# ATSAMD21G17L register map
Vendor: Microchip Technology Inc.; Series: SAMD21; File version: G
CPU: CM0+ r0p1, little endian, no MPU, no FPU, VTOR, 2 interrupt priority bits, 30 interrupts
Registers are 32-bit, read-write, reset 0x0 unless marked. A register's access mark holds for its fields unless they carry their own. Offsets are from the block's base; [hi:lo] are bit positions; lines under a group give offsets from that group; 'fields as' and 'values as' point back to an identical list.

## SERCOM0 — Serial Communication Interface 0
Base 0x42000800; register names take the prefix SERCOM_
Same registers: SERCOM1 0x42000C00, SERCOM2 0x42001000, SERCOM3 0x42001400, SERCOM4 0x42001800, SERCOM5 0x42001C00
0x00 I2CM group — I2C Master Mode
  0x00 CTRLA — I2CM Control A
    [30] LOWTOUTEN — SCL Low Timeout Enable
    [29:28] INACTOUT — Inactive Time-Out
    [27] SCLSM — SCL Clock Stretch Mode
    [25:24] SPEED — Transfer Speed
      0=STANDARD_AND_FAST_MODE (Standard Mode(Sm) Upto 100kHz and Fast Mode(Fm) Upto 400kHz); 1=FASTPLUS_MODE (Fast-mode Plus Upto 1MHz); 2=HIGH_SPEED_MODE (High-speed mode Upto 3.4MHz)
    [23] SEXTTOEN — Slave SCL Low Extend Timeout
    [22] MEXTTOEN — Master SCL Low Extend Timeout
    [21:20] SDAHOLD — SDA Hold Time
      0=DISABLE (Disabled); 1=75NS (50-100ns hold time); 2=450NS (300-600ns hold time); 3=600NS (400-800ns hold time)
    [16] PINOUT — Pin Usage
    [7] RUNSTDBY — Run in Standby
    [4:2] MODE — Operating Mode
      0=USART_EXT_CLK (USART mode with external clock); 1=USART_INT_CLK (USART mode with internal clock); 2=SPI_SLAVE (SPI mode with external clock); 3=SPI_MASTER (SPI mode with internal clock); 4=I2C_SLAVE (I2C mode with external clock); 5=I2C_MASTER (I2C mode with internal clock)
    [1] ENABLE
    [0] SWRST — Software Reset
  0x04 CTRLB — I2CM Control B
    [18] ACKACT — Acknowledge Action
      0=Send_ACK (sending ack); 1=Send_NACK (sending nack)
    [17:16] CMD — Command
      0=no_action; 1=ack_repeated_start (Execute acknowledge action succeeded by repeated Start); 2=ack_byte_read (Execute acknowledge action succeeded by a byte read operation); 3=ack_stop (Execute acknowledge action succeeded by issuing a stop condition)
    [9] QCEN — Quick Command Enable
    [8] SMEN — Smart Mode Enable
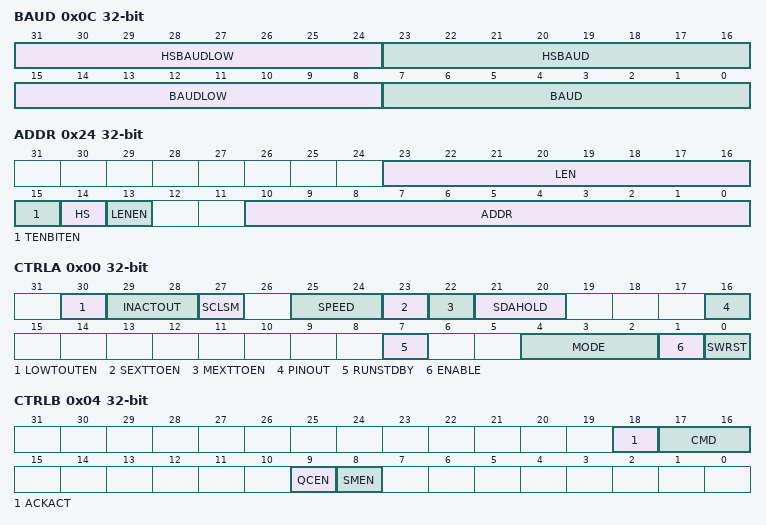
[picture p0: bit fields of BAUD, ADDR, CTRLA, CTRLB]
  0x0C BAUD — I2CM Baud Rate
    [31:24] HSBAUDLOW — High Speed Baud Rate Value Low
    [23:16] HSBAUD — High Speed Baud Rate Value
    [15:8] BAUDLOW — Baud Rate Value Low
    [7:0] BAUD — Baud Rate Value
  0x14 INTENCLR 8-bit — I2CM Interrupt Enable Clear
    [7] ERROR — Combined Error Interrupt Disable
    [1] SB — Slave On Bus Interrupt Disable
    [0] MB — Master On Bus Interrupt Disable
  0x16 INTENSET 8-bit — I2CM Interrupt Enable Set
    [7] ERROR — Combined Error Interrupt Enable
    [1] SB — Slave On Bus Interrupt Enable
    [0] MB — Master On Bus Interrupt Enable
  0x18 INTFLAG 8-bit — I2CM Interrupt Flag Status and Clear
    [7] ERROR write-1-clears — Combined Error Interrupt
    [1] SB write-1-clears — Slave On Bus Interrupt
    [0] MB write-1-clears — Master On Bus Interrupt
  0x1A STATUS 16-bit — I2CM Status
    [10] LENERR write-1-clears — Length Error
    [9] SEXTTOUT write-1-clears — Slave SCL Low Extend Timeout
    [8] MEXTTOUT write-1-clears — Master SCL Low Extend Timeout
    [7] CLKHOLD ro — Clock Hold
    [6] LOWTOUT write-1-clears — SCL Low Timeout
    [5:4] BUSSTATE
      0=unknown (The bus state is unknown to the I2C master and will wait for a stop condition to be detected or wait to be forced into an idle state by software); 1=idle (The bus state is waiting for a transaction to be initialized); 2=owner (The I2C master is the current owner of the bus); 3=busy (Some other I2C master owns the bus)
    [2] RXNACK ro — Received Not Acknowledge
    [1] ARBLOST write-1-clears — Arbitration Lost
    [0] BUSERR write-1-clears — Bus Error
  0x1C SYNCBUSY ro — I2CM Synchronization Busy
    [2] SYSOP — System Operation Synchronization Busy
    [1] ENABLE — SERCOM Enable Synchronization Busy
    [0] SWRST — Software Reset Synchronization Busy
  0x24 ADDR — I2CM Address
    [23:16] LEN — Length
    [15] TENBITEN — Ten Bit Addressing Enable
    [14] HS — High Speed Mode
    [13] LENEN — Length Enable
    [10:0] ADDR — Address Value
  0x28 DATA 8-bit — I2CM Data
    [7:0] DATA — Data Value
  0x30 DBGCTRL 8-bit — I2CM Debug Control
    [0] DBGSTOP — Debug Mode
0x00 I2CS group (alternate view of I2CM) — I2C Slave Mode
  0x00 CTRLA — I2CS Control A
    [30] LOWTOUTEN — SCL Low Timeout Enable
    [27] SCLSM — SCL Clock Stretch Mode
    [25:24] SPEED — Transfer Speed
    [23] SEXTTOEN — Slave SCL Low Extend Timeout
    [21:20] SDAHOLD — SDA Hold Time
    [16] PINOUT — Pin Usage
    [7] RUNSTDBY — Run during Standby
    [4:2] MODE — Operating Mode
      values as I2CM.CTRLA.MODE
    [1] ENABLE
    [0] SWRST — Software Reset
  0x04 CTRLB — I2CS Control B
    [18] ACKACT — Acknowledge Action
    [17:16] CMD wo write-1-sets — Command
    [15:14] AMODE — Address Mode
    [10] AACKEN — Automatic Address Acknowledge
    [9] GCMD — PMBus Group Command
    [8] SMEN — Smart Mode Enable
  0x14 INTENCLR 8-bit — I2CS Interrupt Enable Clear
    [7] ERROR — Combined Error Interrupt Disable
    [2] DRDY — Data Interrupt Disable
    [1] AMATCH — Address Match Interrupt Disable
    [0] PREC — Stop Received Interrupt Disable
  0x16 INTENSET 8-bit — I2CS Interrupt Enable Set
    [7] ERROR — Combined Error Interrupt Enable
    [2] DRDY — Data Interrupt Enable
    [1] AMATCH — Address Match Interrupt Enable
    [0] PREC — Stop Received Interrupt Enable
  0x18 INTFLAG 8-bit — I2CS Interrupt Flag Status and Clear
    [7] ERROR write-1-clears — Combined Error Interrupt
    [2] DRDY write-1-clears — Data Interrupt
    [1] AMATCH write-1-clears — Address Match Interrupt
    [0] PREC write-1-clears — Stop Received Interrupt
  0x1A STATUS 16-bit — I2CS Status
    [10] HS write-1-clears — High Speed
    [9] SEXTTOUT write-1-clears — Slave SCL Low Extend Timeout
    [7] CLKHOLD ro — Clock Hold
    [6] LOWTOUT write-1-clears — SCL Low Timeout
    [4] SR ro — Repeated Start
    [3] DIR ro — Read/Write Direction
    [2] RXNACK ro — Received Not Acknowledge
    [1] COLL write-1-clears — Transmit Collision
    [0] BUSERR write-1-clears — Bus Error
  0x1C SYNCBUSY ro — I2CS Synchronization Busy
    [1] ENABLE — SERCOM Enable Synchronization Busy
    [0] SWRST — Software Reset Synchronization Busy
  0x24 ADDR — I2CS Address
    [26:17] ADDRMASK — Address Mask
    [15] TENBITEN — Ten Bit Addressing Enable
    [10:1] ADDR — Address Value
    [0] GENCEN — General Call Address Enable
  0x28 DATA 8-bit — I2CS Data
    [7:0] DATA — Data Value
0x00 SPI group (alternate view of I2CM) — SPI Mode
  0x00 CTRLA — SPI Control A
    [30] DORD — Data Order
      0=MSB (MSB is transferred first); 1=LSB (LSB is transferred first)
    [29] CPOL — Clock Polarity
    [28] CPHA — Clock Phase
    [27:24] FORM — Frame Format
      0=SPI_FRAME; 2=SPI_FRAME_WITH_ADDR
    [21:20] DIPO — Data In Pinout
    [17:16] DOPO — Data Out Pinout
    [8] IBON — Immediate Buffer Overflow Notification
    [7] RUNSTDBY — Run during Standby
    [4:2] MODE — Operating Mode
      values as I2CM.CTRLA.MODE
    [1] ENABLE
    [0] SWRST — Software Reset
  0x04 CTRLB — SPI Control B
    [17] RXEN — Receiver Enable
    [15:14] AMODE — Address Mode
      0=MASK (SPI Address mask); 1=2_ADDRESSES (Two unique Addressess); 2=RANGE (Address Range)
    [13] MSSEN — Master Slave Select Enable
    [9] SSDE — Slave Select Low Detect Enable
    [6] PLOADEN — Data Preload Enable
    [2:0] CHSIZE — Character Size
      0=8_BIT (8 bits); 1=9_BIT (9 bits)
  0x0C BAUD 8-bit — SPI Baud Rate
    [7:0] BAUD — Baud Rate Value
  0x14 INTENCLR 8-bit — SPI Interrupt Enable Clear
    [7] ERROR — Combined Error Interrupt Disable
    [3] SSL — Slave Select Low Interrupt Disable
    [2] RXC — Receive Complete Interrupt Disable
    [1] TXC — Transmit Complete Interrupt Disable
    [0] DRE — Data Register Empty Interrupt Disable
  0x16 INTENSET 8-bit — SPI Interrupt Enable Set
    [7] ERROR — Combined Error Interrupt Enable
    [3] SSL — Slave Select Low Interrupt Enable
    [2] RXC — Receive Complete Interrupt Enable
    [1] TXC — Transmit Complete Interrupt Enable
    [0] DRE — Data Register Empty Interrupt Enable
  0x18 INTFLAG 8-bit — SPI Interrupt Flag Status and Clear
    [7] ERROR write-1-clears — Combined Error Interrupt
    [3] SSL write-1-clears — Slave Select Low Interrupt Flag
    [2] RXC ro — Receive Complete Interrupt
    [1] TXC write-1-clears — Transmit Complete Interrupt
    [0] DRE ro — Data Register Empty Interrupt
  0x1A STATUS 16-bit — SPI Status
    [2] BUFOVF write-1-clears — Buffer Overflow
  0x1C SYNCBUSY ro — SPI Synchronization Busy
    [2] CTRLB — CTRLB Synchronization Busy
    [1] ENABLE — SERCOM Enable Synchronization Busy
    [0] SWRST — Software Reset Synchronization Busy
  0x24 ADDR — SPI Address
    [23:16] ADDRMASK — Address Mask
    [7:0] ADDR — Address Value
  0x28 DATA — SPI Data
    [8:0] DATA — Data Value
  0x28 DATA8 8-bit — USART Data
    [7:0] DATA — Data Value
  0x30 DBGCTRL 8-bit — SPI Debug Control
    [0] DBGSTOP — Debug Mode
0x00 USART group (alternate view of I2CM) — USART Mode
  0x00 CTRLA — USART Control A
    [30] DORD — Data Order
    [29] CPOL — Clock Polarity
    [28] CMODE — Communication Mode
    [27:24] FORM — Frame Format
    [23:22] SAMPA — Sample Adjustment
    [21:20] RXPO — Receive Data Pinout
    [17:16] TXPO — Transmit Data Pinout
    [15:13] SAMPR — Sample
      0=16X_ARITHMETIC (16x over-sampling using arithmetic baudrate generation); 1=16X_FRACTIONAL (16x over-sampling using fractional baudrate generation); 2=8X_ARITHMETIC (8x over-sampling using arithmetic baudrate generation); 3=8X_FRACTIONAL (8x over-sampling using fractional baudrate generation); 4=3X_ARITHMETIC (3x over-sampling using arithmetic baudrate generation)
    [8] IBON — Immediate Buffer Overflow Notification
    [7] RUNSTDBY — Run during Standby
    [4:2] MODE — Operating Mode
      values as I2CM.CTRLA.MODE
    [1] ENABLE
    [0] SWRST — Software Reset
  0x04 CTRLB — USART Control B
    [17] RXEN — Receiver Enable
    [16] TXEN — Transmitter Enable
    [13] PMODE — Parity Mode
    [10] ENC — Encoding Format
    [9] SFDE — Start of Frame Detection Enable
    [8] COLDEN — Collision Detection Enable
    [6] SBMODE — Stop Bit Mode
    [2:0] CHSIZE — Character Size
      0=8_BIT (8 Bits); 1=9_BIT (9 Bits); 5=5_BIT (5 Bits); 6=6_BIT (6 Bits); 7=7_BIT (7 Bits)
  0x0C BAUD 16-bit — USART Baud Rate
    [15:0] BAUD — Baud Rate Value
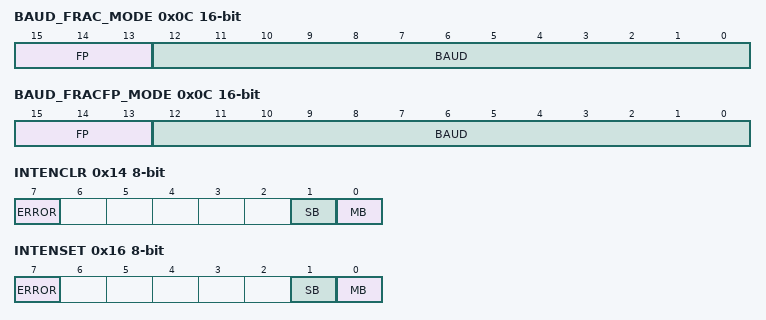
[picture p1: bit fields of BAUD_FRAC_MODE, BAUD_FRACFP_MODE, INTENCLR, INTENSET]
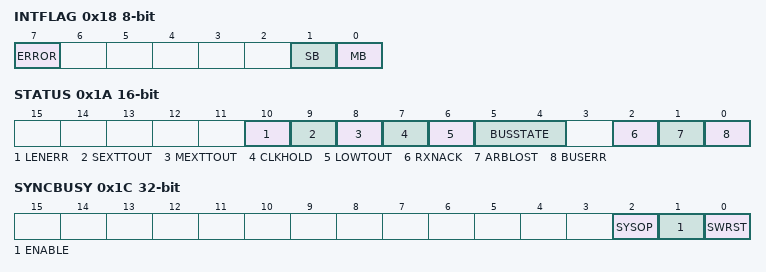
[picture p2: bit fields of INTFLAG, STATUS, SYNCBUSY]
  0x0C BAUD_FRAC_MODE 16-bit (alternate view of BAUD) — USART Baud Rate
    [15:13] FP — Fractional Part
    [12:0] BAUD — Baud Rate Value
  0x0C BAUD_FRACFP_MODE 16-bit (alternate view of BAUD) — USART Baud Rate
    [15:13] FP — Fractional Part
    [12:0] BAUD — Baud Rate Value
  0x0C BAUD_USARTFP_MODE 16-bit (alternate view of BAUD) — USART Baud Rate
    [15:0] BAUD — Baud Rate Value
  0x0E RXPL 8-bit — USART Receive Pulse Length
    [7:0] RXPL — Receive Pulse Length
  0x14 INTENCLR 8-bit — USART Interrupt Enable Clear
    [7] ERROR — Combined Error Interrupt Disable
    [5] RXBRK — Break Received Interrupt Disable
    [4] CTSIC — Clear To Send Input Change Interrupt Disable
    [3] RXS — Receive Start Interrupt Disable
    [2] RXC — Receive Complete Interrupt Disable
    [1] TXC — Transmit Complete Interrupt Disable
    [0] DRE — Data Register Empty Interrupt Disable
  0x16 INTENSET 8-bit — USART Interrupt Enable Set
    [7] ERROR — Combined Error Interrupt Enable
    [5] RXBRK — Break Received Interrupt Enable
    [4] CTSIC — Clear To Send Input Change Interrupt Enable
    [3] RXS — Receive Start Interrupt Enable
    [2] RXC — Receive Complete Interrupt Enable
    [1] TXC — Transmit Complete Interrupt Enable
    [0] DRE — Data Register Empty Interrupt Enable
  0x18 INTFLAG 8-bit — USART Interrupt Flag Status and Clear
    [7] ERROR write-1-clears — Combined Error Interrupt
    [5] RXBRK write-1-clears — Break Received Interrupt
    [4] CTSIC write-1-clears — Clear To Send Input Change Interrupt
    [3] RXS write-1-clears — Receive Start Interrupt
    [2] RXC ro — Receive Complete Interrupt
    [1] TXC write-1-clears — Transmit Complete Interrupt
    [0] DRE ro — Data Register Empty Interrupt
  0x1A STATUS 16-bit — USART Status
    [5] COLL write-1-clears — Collision Detected
    [4] ISF write-1-clears — Inconsistent Sync Field
    [3] CTS ro — Clear To Send
    [2] BUFOVF write-1-clears — Buffer Overflow
    [1] FERR write-1-clears — Frame Error
    [0] PERR write-1-clears — Parity Error
  0x1C SYNCBUSY ro — USART Synchronization Busy
    fields as SPI.SYNCBUSY
  0x28 DATA 16-bit — USART Data
    [8:0] DATA — Data Value
  0x28 DATA8 8-bit — USART Data
    [7:0] DATA — Data Value
  0x30 DBGCTRL 8-bit — USART Debug Control
    [0] DBGSTOP — Debug Mode
